# MB9AF31xK register map
Vendor: Cypress; File version: 2.1
CPU: CM3 r2p1, little endian, MPU, no FPU, 4 interrupt priority bits
Registers are 32-bit, read-write, reset 0x0 unless marked. A register's access mark holds for its fields unless they carry their own. Offsets are from the block's base; [hi:lo] are bit positions; {n}, {i} and the like mark numbered series.

## INTREQ — Interrupts
Base 0x40031000
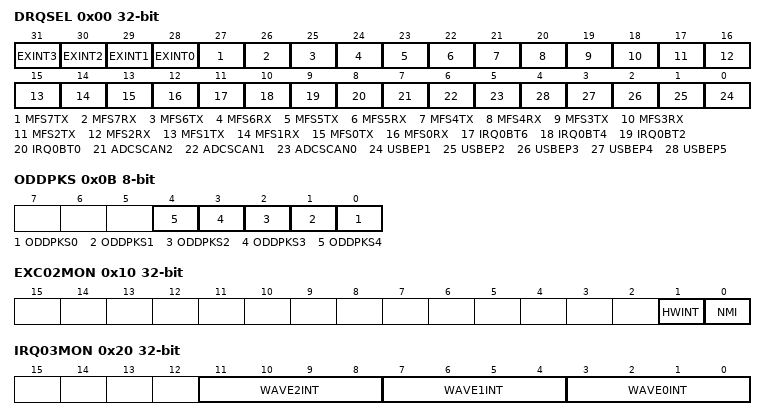
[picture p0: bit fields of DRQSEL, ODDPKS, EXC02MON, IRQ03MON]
0x00 DRQSEL — DMA Request Selection Register [BHW]
  [31] EXINT3 — The interrupt signal of the external interrupt ch.3 is output as a transfer request to the DMAC (including extension)
  [30] EXINT2 — The interrupt signal of the external interrupt ch.2 is output as a transfer request to the DMAC (including extension)
  [29] EXINT1 — The interrupt signal of the external interrupt ch.1 is output as a transfer request to the DMAC (including extension)
  [28] EXINT0 — The interrupt signal of the external interrupt ch.0 is output as a transfer request to the DMAC (including extension)
  [27] MFS7TX — The transmission interrupt signal of the MFS ch.7 is output as a transfer request to the DMAC (including extension)
  [26] MFS7RX — The reception interrupt signal of the MFS ch.7 is output as a transfer request to the DMAC (including extension)
  [25] MFS6TX — The transmission interrupt signal of the MFS ch.6 is output as a transfer request to the DMAC (including extension)
  [24] MFS6RX — The reception interrupt signal of the MFS ch.6 is output as a transfer request to the DMAC (including extension)
  [23] MFS5TX — The transmission interrupt signal of the MFS ch.5 is output as a transfer request to the DMAC (including extension)
  [22] MFS5RX — The reception interrupt signal of the MFS ch.5 is output as a transfer request to the DMAC (including extension)
  [21] MFS4TX — The transmission interrupt signal of the MFS ch.4 is output as a transfer request to the DMAC (including extension)
  [20] MFS4RX — The reception interrupt signal of the MFS ch.4 is output as a transfer request to the DMAC (including extension)
  [19] MFS3TX — The transmission interrupt signal of the MFS ch.3 is output as a transfer request to the DMAC (including extension)
  [18] MFS3RX — The reception interrupt signal of the MFS ch.3 is output as a transfer request to the DMAC (including extension)
  [17] MFS2TX — The transmission interrupt signal of the MFS ch.2 is output as a transfer request to the DMAC (including extension)
  [16] MFS2RX — The reception interrupt signal of the MFS ch.2 is output as a transfer request to the DMAC (including extension)
  [15] MFS1TX — The transmission interrupt signal of the MFS ch.1 is output as a transfer request to the DMAC (including extension)
  [14] MFS1RX — The reception interrupt signal of the MFS ch.1 is output as a transfer request to the DMAC (including extension)
  [13] MFS0TX — The transmission interrupt signal of the MFS ch.0 is output as a transfer request to the DMAC (including extension)
  [12] MFS0RX — The reception interrupt signal of the MFS ch.0 is output as a transfer request to the DMAC (including extension)
  [11] IRQ0BT6 — The IRQ0 interrupt signal of the base timer ch.6 is output as a transfer request to the DMAC
  [10] IRQ0BT4 — The IRQ0 interrupt signal of the base timer ch.4 is output as a transfer request to the DMAC
  [9] IRQ0BT2 — The IRQ0 interrupt signal of the base timer ch.2 is output as a transfer request to the DMAC
  [8] IRQ0BT0 — The IRQ0 interrupt signal of the base timer ch.0 is output as a transfer request to the DMAC
  [7] ADCSCAN2 — The scan conversion interrupt signal of the A/D converter unit 2 is output as a transfer request to the DMAC
  [6] ADCSCAN1 — The scan conversion interrupt signal of the A/D converter unit 1 is output as a transfer request to the DMAC
  [5] ADCSCAN0 — The scan conversion interrupt signal of the A/D converter unit 0 is output as a transfer request to the DMAC
  [n-1] USBEP{n} (n=1..5) — The EP{n} DRQ interrupt signal of the USB ch.0 is output as a transfer request to the DMAC
0x0B ODDPKS 8-bit — USB ch.0 Odd Packet Size DMA Enable Register [B]
  [n] ODDPKS{n} (n=0..4) — The bit width of the last transfer data is converted to Byte when the transfer destination address of DMAC is USB.EP{n+1}DT
0x0C IRQCMODE — Interrupt Factor Vector Relocate Setting Register [BHW]
  [0] IRQCMODE — Interrupt Factor Vector Relocate Setting
0x10 EXC02MON ro — EXC02 batch read register [BHW]
  [1] HWINT — Hardware watchdog timer interrupt request
  [0] NMI — External NMIX pin interrupt request
0x14 IRQ00MON ro — IRQ00 Batch Read Register [BHW]
  [0] FCSINT — Anomalous frequency detection by CSV interrupt request
0x18 IRQ01MON ro — IRQ01 Batch Read Register [BHW]
  [0] SWWDTINT — Software watchdog timer interrupt request
0x1C IRQ02MON ro — IRQ02 Batch Read Register [BHW]
  [0] LVDINT — Low voltage detection (LVD) interrupt request
0x20 IRQ03MON ro — IRQ03 Batch Read Register [BHW]
  [11:8] WAVE2INT — WFG timer/DTIF interrupt requests in MFT unit 2
  [7:4] WAVE1INT — WFG timer/DTIF interrupt requests in MFT unit 1
  [3:0] WAVE0INT — WFG timer/DTIF interrupt requests in MFT unit 0
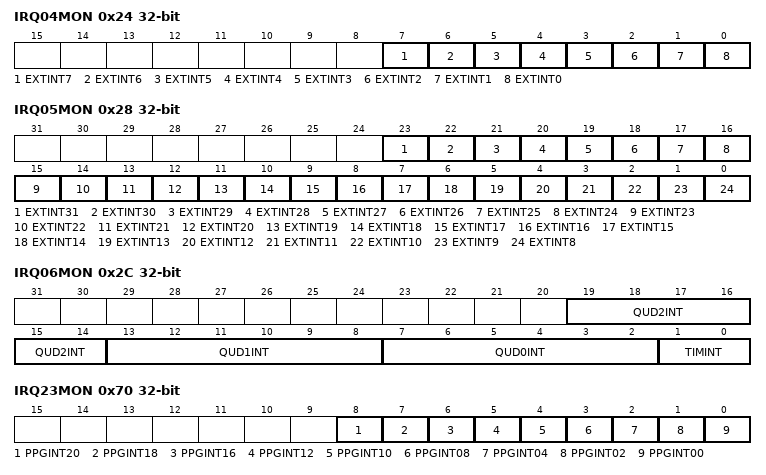
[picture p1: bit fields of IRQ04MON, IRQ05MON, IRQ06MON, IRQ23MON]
0x24 IRQ04MON ro — IRQ04 Batch Read Register [BHW]
  [7] EXTINT7 — Interrupt request on external interrupt ch.7
  [6] EXTINT6 — Interrupt request on external interrupt ch.6
  [5] EXTINT5 — Interrupt request on external interrupt ch.5
  [4] EXTINT4 — Interrupt request on external interrupt ch.4
  [3] EXTINT3 — Interrupt request on external interrupt ch.3
  [2] EXTINT2 — Interrupt request on external interrupt ch.2
  [1] EXTINT1 — Interrupt request on external interrupt ch.1
  [0] EXTINT0 — Interrupt request on external interrupt ch.0
0x28 IRQ05MON ro — IRQ05 Batch Read Register [BHW]
  [23] EXTINT31 — Interrupt request of external interrupt ch.31
  [22] EXTINT30 — Interrupt request of external interrupt ch.30
  [21] EXTINT29 — Interrupt request of external interrupt ch.29
  [20] EXTINT28 — Interrupt request of external interrupt ch.28
  [19] EXTINT27 — Interrupt request of external interrupt ch.27
  [18] EXTINT26 — Interrupt request of external interrupt ch.26
  [17] EXTINT25 — Interrupt request of external interrupt ch.25
  [16] EXTINT24 — Interrupt request of external interrupt ch.24
  [15] EXTINT23 — Interrupt request of external interrupt ch.23
  [14] EXTINT22 — Interrupt request of external interrupt ch.22
  [13] EXTINT21 — Interrupt request of external interrupt ch.21
  [12] EXTINT20 — Interrupt request of external interrupt ch.20
  [11] EXTINT19 — Interrupt request of external interrupt ch.19
  [10] EXTINT18 — Interrupt request of external interrupt ch.18
  [9] EXTINT17 — Interrupt request of external interrupt ch.17
  [8] EXTINT16 — Interrupt request of external interrupt ch.16
  [7] EXTINT15 — Interrupt request of external interrupt ch.15
  [6] EXTINT14 — Interrupt request of external interrupt ch.14
  [5] EXTINT13 — Interrupt request of external interrupt ch.13
  [4] EXTINT12 — Interrupt request of external interrupt ch.12
  [3] EXTINT11 — Interrupt request of external interrupt ch.11
  [2] EXTINT10 — Interrupt request of external interrupt ch.10
  [1] EXTINT9 — Interrupt request of external interrupt ch.9
  [0] EXTINT8 — Interrupt request of external interrupt ch.8
0x2C IRQ06MON ro — IRQ06 Batch Read Register [BHW]
  [19:14] QUD2INT — Interrupt requests of the QPRC ch.2
  [13:8] QUD1INT — Interrupt requests of the QPRC ch.1
  [7:2] QUD0INT — Interrupt requests of the QPRC ch.0
  [1:0] TIMINT — Dual timer interrupt request
0x30 IRQ07MON ro — IRQ07 Batch Read Register [BHW]
  [1:0] MFSINT — Reception interrupt request on MFS ch.0
0x34 IRQ08MON ro — IRQ08 Batch Read Register [BHW]
  [3:0] MFSINT — Transmission interrupt request on MFS ch.0
0x38 IRQ09MON ro — IRQ09 Batch Read Register [BHW]
  [1:0] MFSINT — Reception interrupt request on MFS ch.1
0x3C IRQ10MON ro — IRQ10 Batch Read Register [BHW]
  [3:0] MFSINT — Transmission interrupt request on MFS ch.1
0x40 IRQ11MON ro — IRQ11 Batch Read Register [BHW]
  [1:0] MFSINT — Reception interrupt request on MFS ch.2
0x44 IRQ12MON ro — IRQ12 Batch Read Register [BHW]
  [3:0] MFSINT — Transmission interrupt request on MFS ch.2
0x48 IRQ13MON ro — IRQ13 Batch Read Register [BHW]
  [1:0] MFSINT — Reception interrupt request on MFS ch.3
0x4C IRQ14MON ro — IRQ14 Batch Read Register [BHW]
  [3:0] MFSINT — Transmission interrupt request on MFS ch.3
0x50 IRQ15MON ro — IRQ15 Batch Read Register [BHW]
  [1:0] MFSINT — Reception interrupt request on MFS ch.4
0x54 IRQ16MON ro — IRQ16 Batch Read Register [BHW]
  [3:0] MFSINT — Transmission interrupt request on MFS ch.4
0x58 IRQ17MON ro — IRQ17 Batch Read Register [BHW]
  [1:0] MFSINT — Reception interrupt request on MFS ch.5
0x5C IRQ18MON ro — IRQ18 Batch Read Register [BHW]
  [3:0] MFSINT — Transmission interrupt request on MFS ch.5
0x60 IRQ19MON ro — IRQ19 Batch Read Register [BHW]
  [1:0] MFSINT — Reception interrupt request on MFS ch.6
0x64 IRQ20MON ro — IRQ20 Batch Read Register [BHW]
  [3:0] MFSINT — Transmission interrupt request on MFS ch.6
0x68 IRQ21MON ro — IRQ21 Batch Read Register [BHW]
  [1:0] MFSINT — Reception interrupt request on MFS ch.7
0x6C IRQ22MON ro — IRQ22 Batch Read Register [BHW]
  [3:0] MFSINT — Transmission interrupt request on MFS ch.7
0x70 IRQ23MON ro — IRQ23 Batch Read Register [BHW]
  [8] PPGINT20 — Interrupt request of PPG ch.20
  [7] PPGINT18 — Interrupt request of PPG ch.18
  [6] PPGINT16 — Interrupt request of PPG ch.16
  [5] PPGINT12 — Interrupt request of PPG ch.12
  [4] PPGINT10 — Interrupt request of PPG ch.10
  [3] PPGINT08 — Interrupt request of PPG ch.8
  [2] PPGINT04 — Interrupt request of PPG ch.4
  [1] PPGINT02 — Interrupt request of PPG ch.2
  [0] PPGINT00 — Interrupt request of PPG ch.0
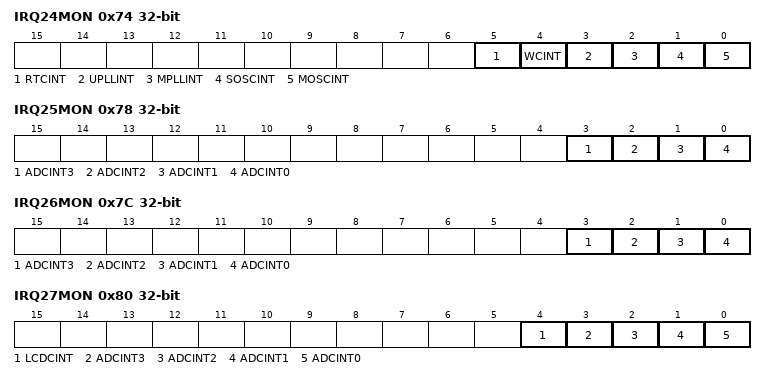
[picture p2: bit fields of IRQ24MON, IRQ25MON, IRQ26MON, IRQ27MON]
0x74 IRQ24MON ro — IRQ24 Batch Read Register [BHW]
  [5] RTCINT — RTC interrupt request
  [4] WCINT — Watch counter interrupt request
  [3] UPLLINT — Stabilization wait completion interrupt request for USB or USB/Ethernet PLL oscillation
  [2] MPLLINT — Stabilization wait completion interrupt request for main PLL oscillation
  [1] SOSCINT — Stabilization wait completion interrupt request for sub-clock oscillation
  [0] MOSCINT — Stabilization wait completion interrupt request for main clock oscillation
0x78 IRQ25MON ro — IRQ25 Batch Read Register [BHW]
  [3] ADCINT3 — Conversion result comparison interrupt request in the corresponding A/D unit 0
  [2] ADCINT2 — FIFO overrun interrupt request in the corresponding A/D unit 0
  [1] ADCINT1 — Scan conversion interrupt request in the corresponding A/D unit 0
  [0] ADCINT0 — Priority conversion interrupt request in the corresponding A/D unit 0
0x7C IRQ26MON ro — IRQ26 Batch Read Register [BHW]
  [3] ADCINT3 — Conversion result comparison interrupt request in the corresponding A/D unit 1
  [2] ADCINT2 — FIFO overrun interrupt request in the corresponding A/D unit 1
  [1] ADCINT1 — Scan conversion interrupt request in the corresponding A/D unit 1
  [0] ADCINT0 — Priority conversion interrupt request in the corresponding A/D unit 1
0x80 IRQ27MON ro — IRQ27 Batch Read Register [BHW]
  [4] LCDCINT — Interrupt request for LCD controller
  [3] ADCINT3 — Conversion result comparison interrupt request in the corresponding A/D unit 2
  [2] ADCINT2 — FIFO overrun interrupt request in the corresponding A/D unit 2
  [1] ADCINT1 — Scan conversion interrupt request in the corresponding A/D unit 2
  [0] ADCINT0 — Priority conversion interrupt request in the corresponding A/D unit 2
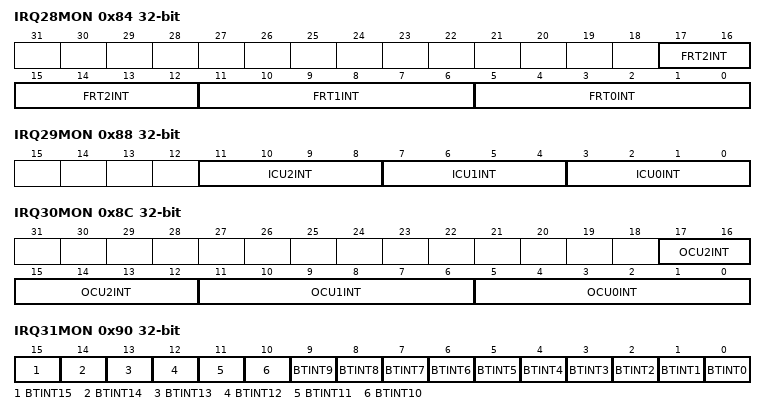
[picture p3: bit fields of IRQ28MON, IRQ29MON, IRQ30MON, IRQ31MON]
0x84 IRQ28MON ro — IRQ28 Batch Read Register [BHW]
  [17:12] FRT2INT — Zero/Peak detection interrupt request of the free run timers in the MFT unit 2
  [11:6] FRT1INT — Zero/Peak detection interrupt request of the free run timers in the MFT unit 1
  [5:0] FRT0INT — Zero/Peak detection interrupt request of the free run timers in the MFT unit 0
0x88 IRQ29MON ro — IRQ29 Batch Read Register [BHW]
  [11:8] ICU2INT — Interrupt request of the input capture in the MFT unit 2
  [7:4] ICU1INT — Interrupt request of the input capture in the MFT unit 1
  [3:0] ICU0INT — Interrupt request of the input capture in the MFT unit 0
0x8C IRQ30MON ro — IRQ30 Batch Read Register [BHW]
  [17:12] OCU2INT — Interrupt request of the output compare in the MFT unit 2
  [11:6] OCU1INT — Interrupt request of the output compare in the MFT unit 1
  [5:0] OCU0INT — Interrupt request of the output compare in the MFT unit 0
0x90 IRQ31MON ro — IRQ31 Batch Read Register [BHW]
  [15] BTINT15 — IRQ1 interrupt request on the base timer ch.7
  [14] BTINT14 — IRQ0 interrupt request on the base timer ch.7
  [13] BTINT13 — IRQ1 interrupt request on the base timer ch.6
  [12] BTINT12 — IRQ0 interrupt request on the base timer ch.6
  [11] BTINT11 — IRQ1 interrupt request on the base timer ch.5
  [10] BTINT10 — IRQ0 interrupt request on the base timer ch.5
  [9] BTINT9 — IRQ1 interrupt request on the base timer ch.4
  [8] BTINT8 — IRQ0 interrupt request on the base timer ch.4
  [7] BTINT7 — IRQ1 interrupt request on the base timer ch.3
  [6] BTINT6 — IRQ0 interrupt request on the base timer ch.3
  [5] BTINT5 — IRQ1 interrupt request on the base timer ch.2
  [4] BTINT4 — IRQ0 interrupt request on the base timer ch.2
  [3] BTINT3 — IRQ1 interrupt request on the base timer ch.1
  [2] BTINT2 — IRQ0 interrupt request on the base timer ch.1
  [1] BTINT1 — IRQ1 interrupt request on the base timer ch.0
  [0] BTINT0 — IRQ0 interrupt request on the base timer ch.0
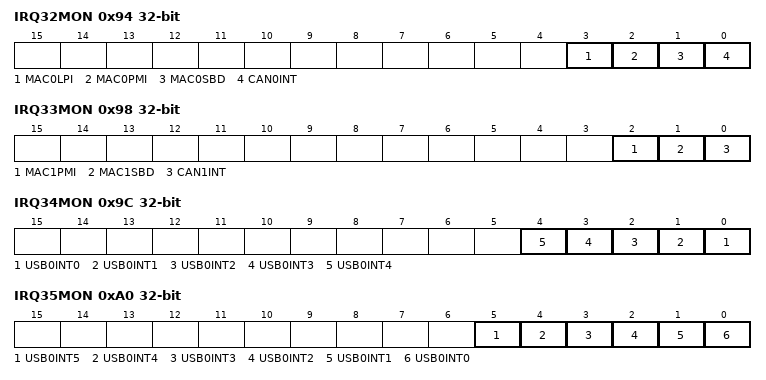
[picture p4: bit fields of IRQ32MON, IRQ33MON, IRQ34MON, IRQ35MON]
0x94 IRQ32MON ro — IRQ32 Batch Read Register [BHW]
  [3] MAC0LPI — LPI interrupt request of Ethernet MAC ch.0
  [2] MAC0PMI — PMI interrupt request of Ethernet MAC ch.0
  [1] MAC0SBD — SBD interrupt request of Ethernet MAC ch.0
  [0] CAN0INT — Interrupt request of CAN ch.0
0x98 IRQ33MON ro — IRQ33 Batch Read Register [BHW]
  [2] MAC1PMI — PMI interrupt request of Ethernet MAC ch.1
  [1] MAC1SBD — SBD interrupt request of Ethernet MAC ch.1
  [0] CAN1INT — Interrupt request of CAN ch.1
0x9C IRQ34MON ro — IRQ34 Batch Read Register [BHW]
  [n] USB0INT{n} (n=0..4) — Endpoint {n+1} DRQ interrupt request on the USB ch.0
0xA0 IRQ35MON ro — IRQ35 Batch Read Register [BHW]
  [5] USB0INT5 — Status (SOFIRQ/CMPIRO) interrupt request on the USB ch.0
  [4] USB0INT4 — Status (DIRQ/URIRQ/RWKIRQ/CNNIRQ) interrupt request on the USB ch.0
  [3] USB0INT3 — Status (SPK) interrupt request on the USB ch.0
  [2] USB0INT2 — Status (SUSP/SOF/BRST/CONF/WKUP) interrupt request on the USB ch.0
  [1] USB0INT1 — Endpoint 0 DRQO interrupt request on the USB ch.0
  [0] USB0INT0 — Endpoint 0 DRQI interrupt request on the USB ch.0
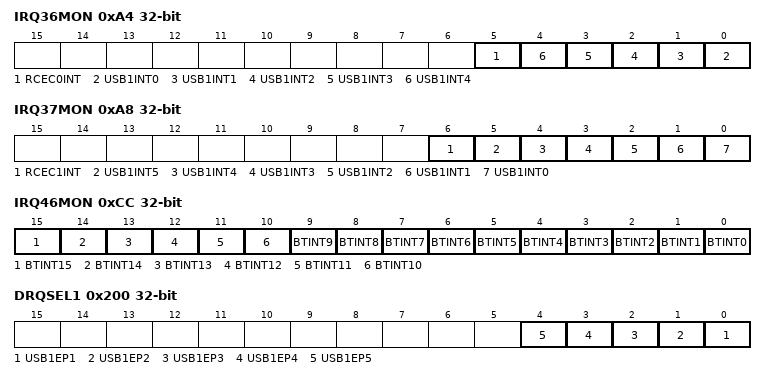
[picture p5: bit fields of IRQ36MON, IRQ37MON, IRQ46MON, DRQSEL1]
0xA4 IRQ36MON ro — IRQ36 Batch Read Register [BHW]
  [5] RCEC0INT — Interrupt request for HDMI-CEC/Remote Control Reception ch.0
  [n] USB1INT{n} (n=0..4) — Endpoint {n+1} DRQ interrupt request on the USB ch.1
0xA8 IRQ37MON ro — IRQ37 Batch Read Register [BHW]
  [6] RCEC1INT — Interrupt request for HDMI-CEC/Remote Control Reception ch.1
  [5] USB1INT5 — Status (SOFIRQ/CMPIRO) interrupt request on the USB ch.1
  [4] USB1INT4 — Status (DIRQ/URIRQ/RWKIRQ/CNNIRQ) interrupt request on the USB ch.1
  [3] USB1INT3 — Status (SPK) interrupt request on the USB ch.1
  [2] USB1INT2 — Status (SUSP/SOF/BRST/CONF/WKUP) interrupt request on the USB ch.1
  [1] USB1INT1 — Endpoint 0 DRQO interrupt request on the USB ch.1
  [0] USB1INT0 — Endpoint 0 DRQI interrupt request on the USB ch.1
0xAC IRQ38MON ro — IRQ38 Batch Read Register [BHW]
  [0] DMAINT — Interrupt request on DMA ch.0
0xB0 IRQ39MON ro — IRQ39 Batch Read Register [BHW]
  [0] DMAINT — Interrupt request on DMA ch.1
0xB4 IRQ40MON ro — IRQ40 Batch Read Register [BHW]
  [0] DMAINT — Interrupt request on DMA ch.2
0xB8 IRQ41MON ro — IRQ41 Batch Read Register [BHW]
  [0] DMAINT — Interrupt request on DMA ch.3
0xBC IRQ42MON ro — IRQ42 Batch Read Register [BHW]
  [0] DMAINT — Interrupt request on DMA ch.4
0xC0 IRQ43MON ro — IRQ43 Batch Read Register [BHW]
  [0] DMAINT — Interrupt request on DMA ch.5
0xC4 IRQ44MON ro — IRQ44 Batch Read Register [BHW]
  [0] DMAINT — Interrupt request on DMA ch.6
0xC8 IRQ45MON ro — IRQ45 Batch Read Register [BHW]
  [0] DMAINT — Interrupt request on DMA ch.7
0xCC IRQ46MON ro — IRQ46 Batch Read Register [BHW]
  [15] BTINT15 — IRQ1 interrupt request on the base timer ch.15
  [14] BTINT14 — IRQ0 interrupt request on the base timer ch.15
  [13] BTINT13 — IRQ1 interrupt request on the base timer ch.14
  [12] BTINT12 — IRQ0 interrupt request on the base timer ch.14
  [11] BTINT11 — IRQ1 interrupt request on the base timer ch.13
  [10] BTINT10 — IRQ0 interrupt request on the base timer ch.13
  [9] BTINT9 — IRQ1 interrupt request on the base timer ch.12
  [8] BTINT8 — IRQ0 interrupt request on the base timer ch.12
  [7] BTINT7 — IRQ1 interrupt request on the base timer ch.11
  [6] BTINT6 — IRQ0 interrupt request on the base timer ch.11
  [5] BTINT5 — IRQ1 interrupt request on the base timer ch.10
  [4] BTINT4 — IRQ0 interrupt request on the base timer ch.10
  [3] BTINT3 — IRQ1 interrupt request on the base timer ch.9
  [2] BTINT2 — IRQ0 interrupt request on the base timer ch.9
  [1] BTINT1 — IRQ1 interrupt request on the base timer ch.8
  [0] BTINT0 — IRQ0 interrupt request on the base timer ch.8
0xD0 IRQ47MON ro — IRQ47 Batch Read Register [BHW]
  [11] FLASHINT — RDY/HANG interrupt request for flash memory
0x200 DRQSEL1 — DMA Request Select Register 1 [BHW]
  [n-1] USB1EP{n} (n=1..5) — Interrupt signal of EP{n} DRQ of USB ch.1 is output to transfer request to DMAC through extended selector
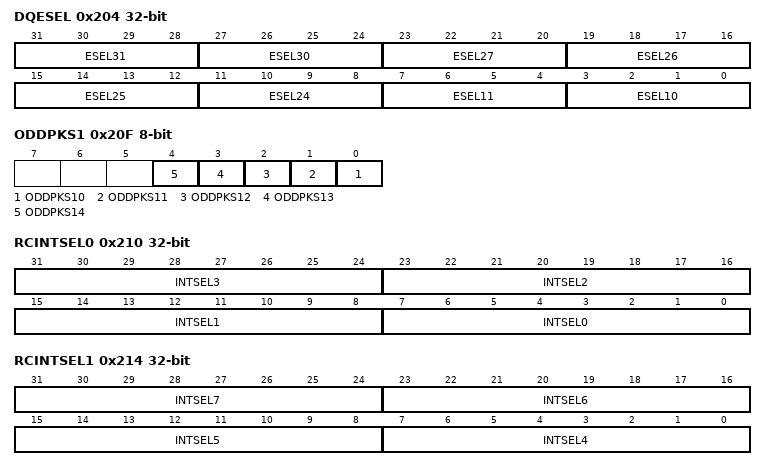
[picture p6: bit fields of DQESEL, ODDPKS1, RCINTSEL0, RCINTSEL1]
0x204 DQESEL — DMA Request Extended Selection Register [BHW]
  [31:28] ESEL31 — Connect USB-ch1 to IDREQ [31]
  [27:24] ESEL30 — Connect USB-ch1 to IDREQ [30]
  [4n-85:4n-88] ESEL{n} (n=24..27) — Connect USB-ch1 to IDREQ [{n}]
  [7:4] ESEL11 — Connect USB-ch1 to IDREQ [11]
  [3:0] ESEL10 — Connect USB-ch1 to IDREQ [10]
0x20F ODDPKS1 8-bit — USB ch.1 Odd Packet Size DMA Enable Register [B]
  [n-10] ODDPKS{n} (n=10..14) — Convert the bit width of the last transfer data to byte when the transfer destination address of the DMAC is USB.EP{n-9}DT
0x210 RCINTSEL0 — Interrupt Factor Selection Register 0 [BHW]
  [31:24] INTSEL3 — Select bits for interrupt factor of interrupt vector No.22
  [23:16] INTSEL2 — Select bits for interrupt factor of interrupt vector No.21
  [15:8] INTSEL1 — Select bits for interrupt factor of interrupt vector No.20
  [7:0] INTSEL0 — Select bits for interrupt factor of interrupt vector No.19
0x214 RCINTSEL1 — Interrupt Factor Selection Register 1 [BHW]
  [31:24] INTSEL7 — Select bits for interrupt factor of interrupt vector No.26
  [23:16] INTSEL6 — Select bits for interrupt factor of interrupt vector No.25
  [15:8] INTSEL5 — Select bits for interrupt factor of interrupt vector No.24
  [7:0] INTSEL4 — Select bits for interrupt factor of interrupt vector No.23
